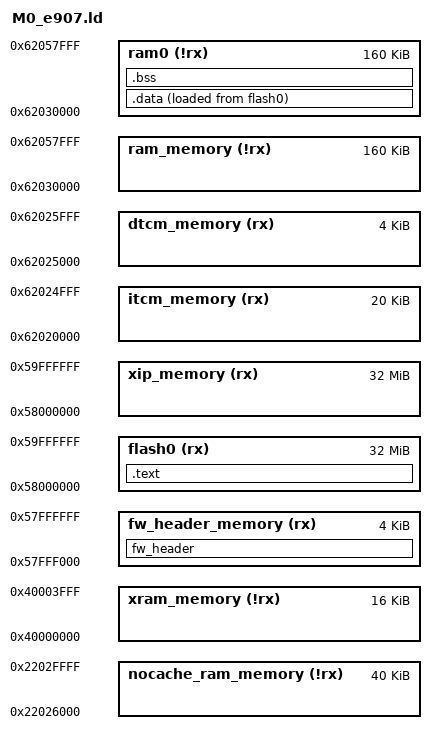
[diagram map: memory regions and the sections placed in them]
/*
 * This file was auto-generated by microzig
 *
 * Target CPU:  e907
 * Target Chip: M0
 */

ENTRY(_start);

MEMORY
{
    fw_header_memory (rx)  : ORIGIN = 0x58000000 - 0x1000, LENGTH = 4K
    flash0  (rx)  : ORIGIN = 0x58000000, LENGTH = 32M
    xip_memory  (rx)  : ORIGIN = 0x58000000, LENGTH = 32M
    itcm_memory (rx)  : ORIGIN = 0x62020000, LENGTH = 20K
    dtcm_memory (rx)  : ORIGIN = 0x62025000, LENGTH = 4K
    nocache_ram_memory (!rx) : ORIGIN = 0x22026000, LENGTH = 40K
    ram_memory  (!rx) : ORIGIN = 0x62030000, LENGTH = 160K + 64K - 20K - 4K - 40K
    ram0  (!rx) : ORIGIN = 0x62030000, LENGTH = 160K + 64K - 20K - 4K - 40K
    xram_memory  (!rx) : ORIGIN = 0x40000000, LENGTH = 16K


  /* fw_header_memory (rx!w) : ORIGIN = 0x58000000 - 0x1000, LENGTH = 0x00001000
  flash0 (rx!w) : ORIGIN = 0x58000000, LENGTH = 0x02000000
  xip_memory (rx!w) : ORIGIN = 0x58000000, LENGTH = 0x02000000
  ram0   (rw!x) : ORIGIN = 0x50000000, LENGTH = 0x04000000
  ram1   (rw!x) : ORIGIN = 0x62020000, LENGTH = 0x00005000
  ram2   (rw!x) : ORIGIN = 0x62025000, LENGTH = 0x00001000
  ram3   (rw!x) : ORIGIN = 0x22026000, LENGTH = 0x00004000
  ram4   (rw!x) : ORIGIN = 0x6202A000, LENGTH = 0x00006000
  ram5   (rw!x) : ORIGIN = 0x22030000, LENGTH = 0x00028000
  ram6   (rw!x) : ORIGIN = 0x40000000, LENGTH = 0x00004000 */
}

SECTIONS
{
  fw_header :
    {
        KEEP(*(bl_fw_header))
    } > fw_header_memory

  .text :
  {
     KEEP(*(microzig_flash_start))
     *(.text*)
  } > flash0

  .data :
  {
    . = ALIGN(4);
     microzig_data_start = .;
     PROVIDE( __global_pointer$ = . + 0x800 );
     *(.rodata*)
     *(.data*)
     microzig_data_end = .;
  } > ram0 AT> flash0

  .bss (NOLOAD) :
  {
      microzig_bss_start = .;
      *(.bss*)
      microzig_bss_end = .;
  } > ram0

  microzig_data_load_start = LOADADDR(.data);
}
